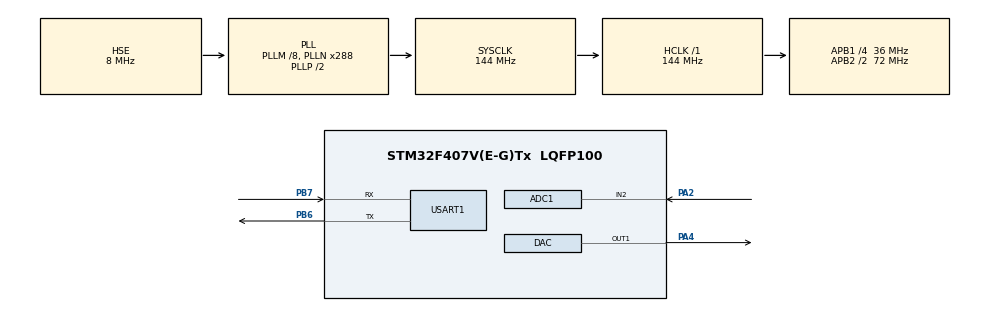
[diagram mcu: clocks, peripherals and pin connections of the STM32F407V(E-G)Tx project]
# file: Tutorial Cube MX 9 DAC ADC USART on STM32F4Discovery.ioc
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ADC1.Channel-0\#ChannelRegularConversion=ADC_CHANNEL_2
ADC1.ContinuousConvMode=ENABLE
ADC1.DMAContinuousRequests=ENABLE
ADC1.EOCSelection=ADC_EOC_SINGLE_CONV
ADC1.NbrOfConversionFlag=1
ADC1.Rank-0\#ChannelRegularConversion=1
ADC1.Resolution=ADC_RESOLUTION_8B
ADC1.SamplingTime-0\#ChannelRegularConversion=ADC_SAMPLETIME_3CYCLES
ADC1.master=1
DAC.DAC_Trigger=DAC_TRIGGER_T4_TRGO
Dma.ADC1.1.Direction=DMA_PERIPH_TO_MEMORY
Dma.ADC1.1.FIFOMode=DMA_FIFOMODE_DISABLE
Dma.ADC1.1.Instance=DMA2_Stream0
Dma.ADC1.1.MemDataAlignment=DMA_MDATAALIGN_BYTE
Dma.ADC1.1.MemInc=DMA_MINC_ENABLE
Dma.ADC1.1.Mode=DMA_CIRCULAR
Dma.ADC1.1.PeriphDataAlignment=DMA_PDATAALIGN_BYTE
Dma.ADC1.1.PeriphInc=DMA_PINC_DISABLE
Dma.ADC1.1.Priority=DMA_PRIORITY_LOW
Dma.DAC1.2.Direction=DMA_MEMORY_TO_PERIPH
Dma.DAC1.2.FIFOMode=DMA_FIFOMODE_DISABLE
Dma.DAC1.2.Instance=DMA1_Stream5
Dma.DAC1.2.MemDataAlignment=DMA_MDATAALIGN_BYTE
Dma.DAC1.2.MemInc=DMA_MINC_ENABLE
Dma.DAC1.2.Mode=DMA_CIRCULAR
Dma.DAC1.2.PeriphDataAlignment=DMA_PDATAALIGN_BYTE
Dma.DAC1.2.PeriphInc=DMA_PINC_DISABLE
Dma.DAC1.2.Priority=DMA_PRIORITY_LOW
Dma.Request0=USART1_TX
Dma.Request1=ADC1
Dma.Request2=DAC1
Dma.USART1_TX.0.Direction=DMA_MEMORY_TO_PERIPH
Dma.USART1_TX.0.FIFOMode=DMA_FIFOMODE_DISABLE
Dma.USART1_TX.0.Instance=DMA2_Stream7
Dma.USART1_TX.0.MemDataAlignment=DMA_MDATAALIGN_BYTE
Dma.USART1_TX.0.MemInc=DMA_MINC_ENABLE
Dma.USART1_TX.0.Mode=DMA_CIRCULAR
Dma.USART1_TX.0.PeriphDataAlignment=DMA_PDATAALIGN_BYTE
Dma.USART1_TX.0.PeriphInc=DMA_PINC_DISABLE
Dma.USART1_TX.0.Priority=DMA_PRIORITY_LOW
Mcu.Family=STM32F4
Mcu.Name=STM32F407V(E-G)Tx
Mcu.Package=LQFP100
NVIC.DMA1_Stream5_IRQn=true\:0\:0\:false\:false\:true
NVIC.DMA2_Stream0_IRQn=true\:0\:0\:false\:false\:true
NVIC.DMA2_Stream7_IRQn=true\:0\:0\:false\:false\:true
NVIC.PriorityGroup=NVIC_PRIORITYGROUP_0
NVIC.TIM4_IRQn=true\:0\:0\:false\:false\:true
PA2.Signal=ADCx_IN2
PA4.Signal=COMP_DAC1_group
PB6.Mode=Asynchronous
PB6.Signal=USART1_TX
PB7.Mode=Asynchronous
PB7.Signal=USART1_RX
PH0-OSC_IN.Mode=HSE-External-Oscillator
PH0-OSC_IN.Signal=RCC_OSC_IN
PH1-OSC_OUT.Mode=HSE-External-Oscillator
PH1-OSC_OUT.Signal=RCC_OSC_OUT
ProjectManager.HeapSize=0x200
ProjectManager.StackSize=0x400
ProjectManager.TargetToolchain=MDK-ARM V5
RCC.48MHZClocksFreq_Value=41142857.14285714
RCC.AHBFreq_Value=144000000
RCC.APB1CLKDivider=RCC_HCLK_DIV4
RCC.APB1Freq_Value=36000000
RCC.APB1TimFreq_Value=72000000
RCC.APB2CLKDivider=RCC_HCLK_DIV2
RCC.APB2Freq_Value=72000000
RCC.APB2TimFreq_Value=144000000
RCC.CortexFreq_Value=144000000
RCC.HCLKFreq_Value=144000000
RCC.HSE_VALUE=8000000
RCC.HSI_VALUE=16000000
RCC.LSE_VALUE=32768
RCC.PLLM=8
RCC.PLLN=288
RCC.PLLQ=7
RCC.PLLSourceVirtual=RCC_PLLSOURCE_HSE
RCC.SYSCLKFreq_VALUE=144000000
RCC.SYSCLKSource=RCC_SYSCLKSOURCE_PLLCLK
RCC.VCOOutputFreq_Value=288000000
SH.ADCx_IN2.0=ADC1_IN2,IN2
SH.COMP_DAC1_group.0=DAC_OUT1,DAC_OUT1
TIM4.Period=1000
TIM4.TIM_MasterOutputTrigger=TIM_TRGO_UPDATE
VP_TIM4_VS_ClockSourceINT.Mode=Internal
board=STM32F407G-DISC1

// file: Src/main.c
/**
  ******************************************************************************
  * File Name          : main.c
  * Description        : Main program body
  ******************************************************************************
  *
  * COPYRIGHT(c) 2016 STMicroelectronics
  *
  * Redistribution and use in source and binary forms, with or without modification,
  * are permitted provided that the following conditions are met:
  *   1. Redistributions of source code must retain the above copyright notice,
  *      this list of conditions and the following disclaimer.
  *   2. Redistributions in binary form must reproduce the above copyright notice,
  *      this list of conditions and the following disclaimer in the documentation
  *      and/or other materials provided with the distribution.
  *   3. Neither the name of STMicroelectronics nor the names of its contributors
  *      may be used to endorse or promote products derived from this software
  *      without specific prior written permission.
  *
  * THIS SOFTWARE IS PROVIDED BY THE COPYRIGHT HOLDERS AND CONTRIBUTORS "AS IS"
  * AND ANY EXPRESS OR IMPLIED WARRANTIES, INCLUDING, BUT NOT LIMITED TO, THE
  * IMPLIED WARRANTIES OF MERCHANTABILITY AND FITNESS FOR A PARTICULAR PURPOSE ARE
  * DISCLAIMED. IN NO EVENT SHALL THE COPYRIGHT HOLDER OR CONTRIBUTORS BE LIABLE
  * FOR ANY DIRECT, INDIRECT, INCIDENTAL, SPECIAL, EXEMPLARY, OR CONSEQUENTIAL
  * DAMAGES (INCLUDING, BUT NOT LIMITED TO, PROCUREMENT OF SUBSTITUTE GOODS OR
  * SERVICES; LOSS OF USE, DATA, OR PROFITS; OR BUSINESS INTERRUPTION) HOWEVER
  * CAUSED AND ON ANY THEORY OF LIABILITY, WHETHER IN CONTRACT, STRICT LIABILITY,
  * OR TORT (INCLUDING NEGLIGENCE OR OTHERWISE) ARISING IN ANY WAY OUT OF THE USE
  * OF THIS SOFTWARE, EVEN IF ADVISED OF THE POSSIBILITY OF SUCH DAMAGE.
  *
  ******************************************************************************
  */
#include "stm32f4xx_hal.h"

/* USER CODE BEGIN Includes */
#include "math.h"
/* USER CODE END Includes */

ADC_HandleTypeDef hadc1;
DMA_HandleTypeDef hdma_adc1;

DAC_HandleTypeDef hdac;
DMA_HandleTypeDef hdma_dac1;

TIM_HandleTypeDef htim4;

UART_HandleTypeDef huart1;
DMA_HandleTypeDef hdma_usart1_tx;

/* USER CODE BEGIN PV */
/* Private variables ---------------------------------------------------------*/
uint16_t i,j;
uint8_t bufferIn[256],bufferOut[256];
/* USER CODE END PV */

void SystemClock_Config(void);
void Error_Handler(void);
static void MX_GPIO_Init(void);
static void MX_DMA_Init(void);
static void MX_ADC1_Init(void);
static void MX_DAC_Init(void);
static void MX_USART1_UART_Init(void);
static void MX_TIM4_Init(void);

/* USER CODE BEGIN PFP */
/* Private function prototypes -----------------------------------------------*/

/* USER CODE END PFP */

int main(void)
{

  /* MCU Configuration----------------------------------------------------------*/

  /* Reset of all peripherals, Initializes the Flash interface and the Systick. */
  HAL_Init();

  /* Configure the system clock */
  SystemClock_Config();

  /* Initialize all configured peripherals */
  MX_GPIO_Init();
  MX_DMA_Init();
  MX_ADC1_Init();
  MX_DAC_Init();
  MX_USART1_UART_Init();
  MX_TIM4_Init();

  /* USER CODE BEGIN 2 */
	// ex:1 DAC to ADC
//	for(i = 0;i < 256; i++){
//		bufferIn[i] = i;
//	}
//	HAL_DAC_Start(&hdac, DAC_CHANNEL_1);
//	HAL_ADC_Start(&hadc1);
//	HAL_UART_Transmit_DMA(&huart1, (uint8_t *) bufferOut, 256);

//	i = 0;

	// ex:2 DAC to ADC  (sin wave)
//	for(i = 0;i < 256; i++){
//		bufferIn[i] = (int) 120*sin(6.28 *i/256);
//	}
//	HAL_DAC_Start(&hdac, DAC_CHANNEL_1);
//	HAL_ADC_Start(&hadc1);
//	HAL_UART_Transmit_DMA(&huart1, (uint8_t *) bufferOut, 256);
//	i = 0;

	// ex:3 DAC to ADC by DMA
	for(i = 0;i < 256; i++){
		bufferIn[i] = (int) 120*sin(6.28 *i/256);
	}
	HAL_TIM_Base_Start(&htim4);
	HAL_DAC_Start_DMA(&hdac, DAC_CHANNEL_1, (uint32_t*) bufferIn, 256, DAC_ALIGN_8B_R);
	HAL_ADC_Start_DMA(&hadc1,(uint32_t*) bufferOut, 32 );
	HAL_UART_Transmit_DMA(&huart1, (uint8_t *) bufferOut, 32);
	i = 0;
  /* USER CODE END 2 */

  /* Infinite loop */
  while (1)
  {
// 		DAC write data, and ADC read data.
//		i++;
//		if (i>255) i=0;
//		HAL_DAC_SetValue(&hdac, DAC_CHANNEL_1, DAC_ALIGN_8B_R, bufferIn[i]);
//		for (j=0;j<10000;j++);
//		bufferOut[i] = HAL_ADC_GetValue(&hadc1);
  }

}

/** System Clock Configuration
*/
void SystemClock_Config(void)
{

  RCC_OscInitTypeDef RCC_OscInitStruct;
  RCC_ClkInitTypeDef RCC_ClkInitStruct;

  __HAL_RCC_PWR_CLK_ENABLE();

  __HAL_PWR_VOLTAGESCALING_CONFIG(PWR_REGULATOR_VOLTAGE_SCALE1);

  RCC_OscInitStruct.OscillatorType = RCC_OSCILLATORTYPE_HSE;
  RCC_OscInitStruct.HSEState = RCC_HSE_ON;
  RCC_OscInitStruct.PLL.PLLState = RCC_PLL_ON;
  RCC_OscInitStruct.PLL.PLLSource = RCC_PLLSOURCE_HSE;
  RCC_OscInitStruct.PLL.PLLM = 8;
  RCC_OscInitStruct.PLL.PLLN = 288;
  RCC_OscInitStruct.PLL.PLLP = RCC_PLLP_DIV2;
  RCC_OscInitStruct.PLL.PLLQ = 7;
  if (HAL_RCC_OscConfig(&RCC_OscInitStruct) != HAL_OK)
  {
    Error_Handler();
  }

  RCC_ClkInitStruct.ClockType = RCC_CLOCKTYPE_HCLK|RCC_CLOCKTYPE_SYSCLK
                              |RCC_CLOCKTYPE_PCLK1|RCC_CLOCKTYPE_PCLK2;
  RCC_ClkInitStruct.SYSCLKSource = RCC_SYSCLKSOURCE_PLLCLK;
  RCC_ClkInitStruct.AHBCLKDivider = RCC_SYSCLK_DIV1;
  RCC_ClkInitStruct.APB1CLKDivider = RCC_HCLK_DIV4;
  RCC_ClkInitStruct.APB2CLKDivider = RCC_HCLK_DIV2;
  if (HAL_RCC_ClockConfig(&RCC_ClkInitStruct, FLASH_LATENCY_4) != HAL_OK)
  {
    Error_Handler();
  }

  HAL_SYSTICK_Config(HAL_RCC_GetHCLKFreq()/1000);

  HAL_SYSTICK_CLKSourceConfig(SYSTICK_CLKSOURCE_HCLK);

  /* SysTick_IRQn interrupt configuration */
  HAL_NVIC_SetPriority(SysTick_IRQn, 0, 0);
}

/* ADC1 init function */
static void MX_ADC1_Init(void)
{

  ADC_ChannelConfTypeDef sConfig;

    /**Configure the global features of the ADC (Clock, Resolution, Data Alignment and number of conversion)
    */
  hadc1.Instance = ADC1;
  hadc1.Init.ClockPrescaler = ADC_CLOCK_SYNC_PCLK_DIV2;
  hadc1.Init.Resolution = ADC_RESOLUTION_8B;
  hadc1.Init.ScanConvMode = DISABLE;
  hadc1.Init.ContinuousConvMode = ENABLE;
  hadc1.Init.DiscontinuousConvMode = DISABLE;
  hadc1.Init.ExternalTrigConvEdge = ADC_EXTERNALTRIGCONVEDGE_NONE;
  hadc1.Init.DataAlign = ADC_DATAALIGN_RIGHT;
  hadc1.Init.NbrOfConversion = 1;
  hadc1.Init.DMAContinuousRequests = ENABLE;
  hadc1.Init.EOCSelection = ADC_EOC_SINGLE_CONV;
  if (HAL_ADC_Init(&hadc1) != HAL_OK)
  {
    Error_Handler();
  }

    /**Configure for the selected ADC regular channel its corresponding rank in the sequencer and its sample time.
    */
  sConfig.Channel = ADC_CHANNEL_2;
  sConfig.Rank = 1;
  sConfig.SamplingTime = ADC_SAMPLETIME_3CYCLES;
  if (HAL_ADC_ConfigChannel(&hadc1, &sConfig) != HAL_OK)
  {
    Error_Handler();
  }

}

/* DAC init function */
static void MX_DAC_Init(void)
{

  DAC_ChannelConfTypeDef sConfig;

    /**DAC Initialization
    */
  hdac.Instance = DAC;
  if (HAL_DAC_Init(&hdac) != HAL_OK)
  {
    Error_Handler();
  }

    /**DAC channel OUT1 config
    */
  sConfig.DAC_Trigger = DAC_TRIGGER_T4_TRGO;
  sConfig.DAC_OutputBuffer = DAC_OUTPUTBUFFER_ENABLE;
  if (HAL_DAC_ConfigChannel(&hdac, &sConfig, DAC_CHANNEL_1) != HAL_OK)
  {
    Error_Handler();
  }

}

/* TIM4 init function */
static void MX_TIM4_Init(void)
{

  TIM_ClockConfigTypeDef sClockSourceConfig;
  TIM_MasterConfigTypeDef sMasterConfig;

  htim4.Instance = TIM4;
  htim4.Init.Prescaler = 0;
  htim4.Init.CounterMode = TIM_COUNTERMODE_UP;
  htim4.Init.Period = 1000;
  htim4.Init.ClockDivision = TIM_CLOCKDIVISION_DIV1;
  if (HAL_TIM_Base_Init(&htim4) != HAL_OK)
  {
    Error_Handler();
  }

  sClockSourceConfig.ClockSource = TIM_CLOCKSOURCE_INTERNAL;
  if (HAL_TIM_ConfigClockSource(&htim4, &sClockSourceConfig) != HAL_OK)
  {
    Error_Handler();
  }

  sMasterConfig.MasterOutputTrigger = TIM_TRGO_UPDATE;
  sMasterConfig.MasterSlaveMode = TIM_MASTERSLAVEMODE_DISABLE;
  if (HAL_TIMEx_MasterConfigSynchronization(&htim4, &sMasterConfig) != HAL_OK)
  {
    Error_Handler();
  }

}

/* USART1 init function */
static void MX_USART1_UART_Init(void)
{

  huart1.Instance = USART1;
  huart1.Init.BaudRate = 115200;
  huart1.Init.WordLength = UART_WORDLENGTH_8B;
  huart1.Init.StopBits = UART_STOPBITS_1;
  huart1.Init.Parity = UART_PARITY_NONE;
  huart1.Init.Mode = UART_MODE_TX_RX;
  huart1.Init.HwFlowCtl = UART_HWCONTROL_NONE;
  huart1.Init.OverSampling = UART_OVERSAMPLING_16;
  if (HAL_UART_Init(&huart1) != HAL_OK)
  {
    Error_Handler();
  }

}

static void MX_DMA_Init(void)
{
  /* DMA controller clock enable */
  __HAL_RCC_DMA2_CLK_ENABLE();
  __HAL_RCC_DMA1_CLK_ENABLE();

  /* DMA interrupt init */
  /* DMA1_Stream5_IRQn interrupt configuration */
  HAL_NVIC_SetPriority(DMA1_Stream5_IRQn, 0, 0);
  HAL_NVIC_EnableIRQ(DMA1_Stream5_IRQn);
  /* DMA2_Stream0_IRQn interrupt configuration */
  HAL_NVIC_SetPriority(DMA2_Stream0_IRQn, 0, 0);
  HAL_NVIC_EnableIRQ(DMA2_Stream0_IRQn);
  /* DMA2_Stream7_IRQn interrupt configuration */
  HAL_NVIC_SetPriority(DMA2_Stream7_IRQn, 0, 0);
  HAL_NVIC_EnableIRQ(DMA2_Stream7_IRQn);

}

/** Configure pins as
        * Analog
        * Input
        * Output
        * EVENT_OUT
        * EXTI
*/
static void MX_GPIO_Init(void)
{

  /* GPIO Ports Clock Enable */
  __HAL_RCC_GPIOH_CLK_ENABLE();
  __HAL_RCC_GPIOA_CLK_ENABLE();
  __HAL_RCC_GPIOB_CLK_ENABLE();

}

void Error_Handler(void)
{
  while(1)
  {
  }
}

/************************ (C) COPYRIGHT STMicroelectronics *****END OF FILE****/
